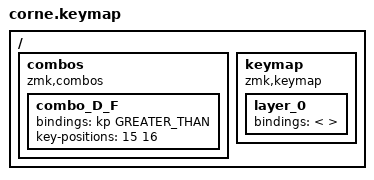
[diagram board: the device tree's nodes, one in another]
#include <behaviors.dtsi>
#include <dt-bindings/zmk/keys.h>

/ {
    combos {
        compatible = "zmk,combos";

        combo_D_F {
            bindings = <&kp GREATER_THAN>;
            key-positions = <15 16>;
        };
    };

    keymap {
        compatible = "zmk,keymap";

        layer_0 {
            bindings = <

            >;
        };
    };
};
